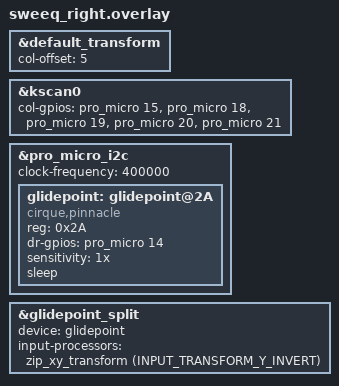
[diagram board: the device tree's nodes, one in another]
#include "sweeq.dtsi"

&default_transform {
    col-offset = <5>;
};

&kscan0 {
    col-gpios
        = <&pro_micro 15 GPIO_ACTIVE_HIGH>
        , <&pro_micro 18 GPIO_ACTIVE_HIGH>
        , <&pro_micro 19 GPIO_ACTIVE_HIGH>
        , <&pro_micro 20 GPIO_ACTIVE_HIGH>
        , <&pro_micro 21 GPIO_ACTIVE_HIGH>
        ;
};

&pro_micro_i2c {
    status = "okay";
    clock-frequency = < 400000 >;

    glidepoint: glidepoint@2A {
        compatible = "cirque,pinnacle";
        reg = <0x2A>;
        status = "okay";
        dr-gpios= <&pro_micro 14 (GPIO_ACTIVE_HIGH)>;
        //y-invert;

        sensitivity = "1x";
        sleep;
        //no-taps;

    };

};

&glidepoint_split {
    device = <&glidepoint>;

    // Optional
    // input-processors = <&zip_xy_transform (INPUT_TRANSFORM_XY_SWAP | INPUT_TRANSFORM_X_INVERT | INPUT_TRANSFORM_Y_INVERT)>;
    input-processors = <&zip_xy_transform (INPUT_TRANSFORM_Y_INVERT)>;
};
